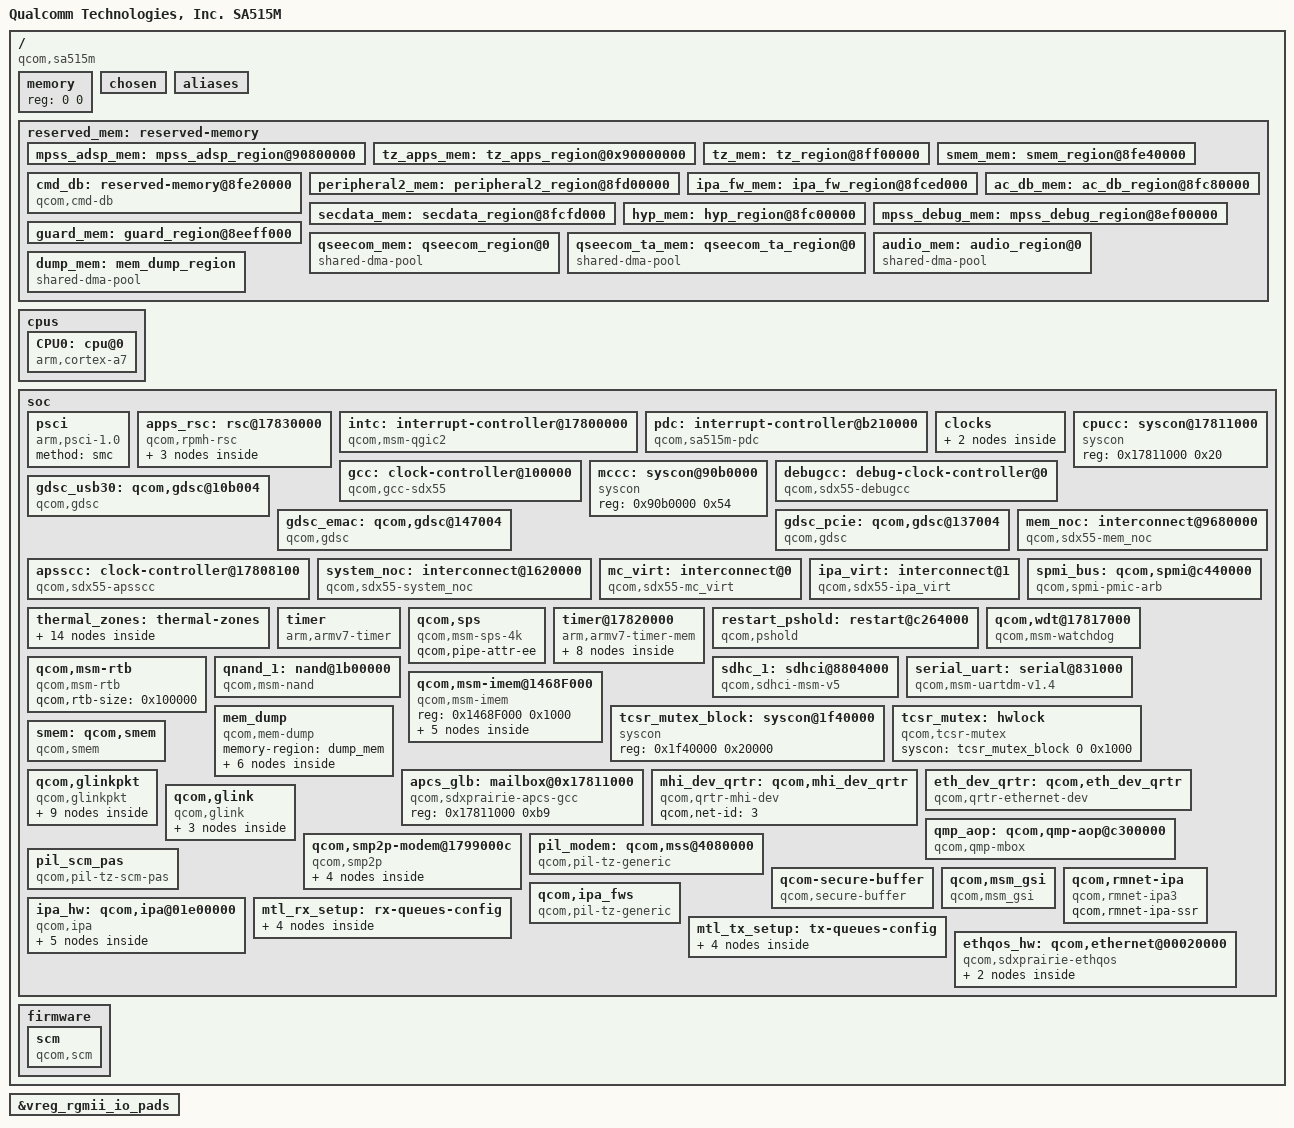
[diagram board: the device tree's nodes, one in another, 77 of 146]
#include <dt-bindings/clock/qcom,gcc-sdx55.h>
#include <dt-bindings/clock/qcom,rpmh.h>
#include <dt-bindings/interconnect/qcom,icc.h>
#include <dt-bindings/interconnect/qcom,sdx55.h>
#include <dt-bindings/interrupt-controller/arm-gic.h>
#include <dt-bindings/regulator/qcom,rpmh-regulator-levels.h>
#include <dt-bindings/soc/qcom,rpmh-rsc.h>
#include <dt-bindings/gpio/gpio.h>

/ {
	#address-cells = <1>;
	#size-cells = <1>;
	model = "Qualcomm Technologies, Inc. SA515M";
	compatible = "qcom,sa515m";
	qcom,msm-id = <418 0x10000>;

	interrupt-parent = <&intc>;

	memory { device_type = "memory"; reg = <0 0>; };

	chosen: chosen { };

	aliases {
		pci-domain0 = &pcie0; /* PCIe0 domain */
		sdhc1 = &sdhc_1; /* SDC1 eMMC/SD/SDIO slot */
	};

	reserved_mem: reserved-memory {
		#address-cells = <1>;
		#size-cells = <1>;
		ranges;

		mpss_adsp_mem: mpss_adsp_region@90800000 {
			no-map;
			reg = <0x90800000 0xe000000>;
			label = "mpss_adsp_mem";
		};

		tz_apps_mem: tz_apps_region@0x90000000 {
			no-map;
			reg = <0x90000000 0x500000>;
			label = "tz_apps_mem";
		};

		tz_mem: tz_region@8ff00000 {
			no-map;
			reg = <0x8ff00000 0x100000>;
			label = "tz_mem";
		};

		smem_mem: smem_region@8fe40000 {
			no-map;
			reg = <0x8fe40000 0xc0000>;
			label = "smem_mem";
		};

		cmd_db: reserved-memory@8fe20000 {
			compatible = "qcom,cmd-db";
			no-map;
			reg = <0x8fe20000 0x20000>;
		};

		peripheral2_mem: peripheral2_region@8fd00000 {
			no-map;
			reg = <0x8fd00000 0x120000>;
			label = "peripheral2_mem";
		};

		ipa_fw_mem: ipa_fw_region@8fced000 {
			no-map;
			reg = <0x8fced000 0x10000>;
			label = "ipa_fw_mem";
		};

		secdata_mem: secdata_region@8fcfd000 {
			no-map;
			reg = <0x8fcfd000 0x1000>;
			label = "secdata_mem";
		};

		ac_db_mem: ac_db_region@8fc80000 {
			no-map;
			reg = <0x8fc80000 0x40000>;
			label = "ac_db_mem";
		};

		hyp_mem: hyp_region@8fc00000 {
			no-map;
			reg = <0x8fc00000 0x80000>;
			label = "hyp_mem";
		};

		mpss_debug_mem: mpss_debug_region@8ef00000 {
			no-map;
			reg = <0x8ef00000 0x800000>;
			label = "mpss_debug_mem";
		};

		guard_mem: guard_region@8eeff000 {
			no-map;
			reg = <0x8eeff000 0x1000>;
			label = "guard_mem";
		};

		qseecom_mem: qseecom_region@0 {
			compatible = "shared-dma-pool";
			reusable;
			alignment = <0x400000>;
			size = <0x1400000>;
		};

		qseecom_ta_mem: qseecom_ta_region@0 {
			compatible = "shared-dma-pool";
			reusable;
			alignment = <0x400000>;
			size = <0x400000>;
		};

		audio_mem: audio_region@0 {
			compatible = "shared-dma-pool";
			no-map;
			size = <0x400000>;
		};

		dump_mem: mem_dump_region {
			compatible = "shared-dma-pool";
			reusable;
			size = <0x400000>;
		};
	};

	cpus {
		#size-cells = <0>;
		#address-cells = <1>;

		CPU0: cpu@0 {
			device_type = "cpu";
			compatible = "arm,cortex-a7";
			reg = <0x0>;
			enable-method = "psci";
			cpu-idle-states = <&A7_SPC &A7_PC &CX_MIN>;
			#cooling-cells = <2>;
		};
	};

	soc: soc { };

	firmware: firmware {};
};

&soc {
	#address-cells = <1>;
	#size-cells = <1>;
	ranges;

	psci {
		compatible = "arm,psci-1.0";
		method = "smc";
	};

	apps_rsc: rsc@17830000 {
		label = "apps_rsc";
		compatible = "qcom,rpmh-rsc";
		reg = <0x17830000 0x10000>,
		      <0x17840000 0x10000>;
		reg-names = "drv-0", "drv-1";
		interrupts = <GIC_SPI 16 IRQ_TYPE_LEVEL_HIGH>,
			     <GIC_SPI 17 IRQ_TYPE_LEVEL_HIGH>;
		qcom,tcs-offset = <0xd00>;
		qcom,drv-id = <1>;
		qcom,tcs-config = <ACTIVE_TCS  2>,
				  <SLEEP_TCS   2>,
				  <WAKE_TCS    2>,
				  <CONTROL_TCS 1>;

		rpmhcc: qcom,rpmh {
			compatible = "qcom,sdx55-rpmh-clk";
			clocks = <&xo_board>;
			clock-names = "xo";
			#clock-cells = <1>;
		};

		apps_bcm_voter: bcm_voter {
			compatible = "qcom,bcm-voter";
		};

		system_pm {
			compatible = "qcom,system-pm";
		};
	};

	intc: interrupt-controller@17800000 {
		compatible = "qcom,msm-qgic2";
		interrupt-controller;
		interrupt-parent = <&intc>;
		#interrupt-cells = <3>;
		reg = <0x17800000 0x1000>,
		      <0x17802000 0x1000>;
	};

	pdc: interrupt-controller@b210000 {
		compatible = "qcom,sa515m-pdc";
		reg = <0xb210000 0x30000>,
		      <0xb204900 0x700>;
		reg-names = "base", "mux-base";
		qcom,pdc-ranges = <0 147 52>;
		qcom,pdc-mux-ranges = <20 28 0>, <21 32 1>, <22 35 2>,
				      <23 57 3>, <24 49 4>, <25 58 5>;
		#interrupt-cells = <2>;
		interrupt-parent = <&intc>;
		interrupt-controller;
	};

	clocks {
		xo_board: xo-board {
			compatible = "fixed-clock";
			clock-frequency = <38400000>;
			clock-output-names = "xo_board";
			#clock-cells = <0>;
		};

		sleep_clk: sleep-clk {
			compatible = "fixed-clock";
			clock-frequency = <32000>;
			clock-output-names = "sleep_clk";
			#clock-cells = <0>;
		};
	};

	gcc: clock-controller@100000 {
		compatible = "qcom,gcc-sdx55", "syscon";
		reg = <0x100000 0x1f0000>;
		reg-names = "cc_base";
		clocks = <&rpmhcc RPMH_CXO_CLK>, <&rpmhcc RPMH_CXO_CLK_A>,
			<&sleep_clk>;
		clock-names = "bi_tcxo", "bi_tcxo_ao", "sleep_clk";
		vdd_cx-supply = <&VDD_CX_LEVEL>;
		vdd_cx_ao-supply = <&VDD_CX_LEVEL_AO>;
		vdd_mx-supply = <&VDD_MX_LEVEL>;
		#clock-cells = <1>;
		#reset-cells = <1>;
	};

	cpucc: syscon@17811000 {
		compatible = "syscon";
		reg = <0x17811000 0x20>;
	};

	mccc: syscon@90b0000 {
		compatible = "syscon";
		reg = <0x90b0000 0x54>;
	};

	debugcc: debug-clock-controller@0 {
		compatible = "qcom,sdx55-debugcc";
		qcom,gcc = <&gcc>;
		qcom,apsscc = <&cpucc>;
		qcom,mccc = <&mccc>;
		clock-names = "xo_clk_src";
		clocks = <&rpmhcc RPMH_CXO_CLK>;
		#clock-cells = <1>;
	};

	/* GDSCs in Global CC */
	gdsc_usb30: qcom,gdsc@10b004 {
		compatible = "qcom,gdsc";
		regulator-name = "gdsc_usb30";
		reg = <0x10b004 0x4>;
	};

	gdsc_emac: qcom,gdsc@147004 {
		compatible = "qcom,gdsc";
		regulator-name = "gdsc_emac";
		reg = <0x147004 0x4>;
	};

	gdsc_pcie: qcom,gdsc@137004 {
		compatible = "qcom,gdsc";
		regulator-name = "gdsc_pcie";
		reg = <0x137004 0x4>;
	};

	apsscc: clock-controller@17808100 {
		compatible = "qcom,sdx55-apsscc";
		clocks = <&rpmhcc RPMH_CXO_CLK_A>,
			<&gcc GPLL0>;
		clock-names = "bi_tcxo_ao", "gpll0_out_even";
		reg = <0x17810008 0x8>,
			<0x17808100 0x44>;
		reg-names = "apcs_cmd" , "apcs_pll";
		vdd-pll-supply = <&VDD_CX_LEVEL_AO>;
		cpu-vdd-supply = <&VDD_CX_LEVEL_AO>;
		qcom,speed0-bin-v0 =
			< 0 0>,
			<  345600000 RPMH_REGULATOR_LEVEL_LOW_SVS>,
			<  576000000 RPMH_REGULATOR_LEVEL_SVS>,
			< 1094400000 RPMH_REGULATOR_LEVEL_NOM>,
			< 1555200000 RPMH_REGULATOR_LEVEL_TURBO>;
		#clock-cells = <1>;
	};

	system_noc: interconnect@1620000 {
		compatible = "qcom,sdx55-system_noc";
		reg = <0x1620000 0x31200>;
		#interconnect-cells = <1>;
		qcom,bcm-voter-names = "hlos";
		qcom,bcm-voters = <&apps_bcm_voter>;
	};

	mem_noc: interconnect@9680000 {
		compatible = "qcom,sdx55-mem_noc";
		reg = <0x9680000 0x27200>;
		#interconnect-cells = <1>;
		qcom,bcm-voter-names = "hlos";
		qcom,bcm-voters = <&apps_bcm_voter>;
	};

	mc_virt: interconnect@0 {
		compatible = "qcom,sdx55-mc_virt";
		#interconnect-cells = <1>;
		qcom,bcm-voter-names = "hlos";
		qcom,bcm-voters = <&apps_bcm_voter>;
	};

	ipa_virt: interconnect@1 {
		compatible = "qcom,sdx55-ipa_virt";
		#interconnect-cells = <1>;
		qcom,bcm-voter-names = "hlos";
		qcom,bcm-voters = <&apps_bcm_voter>;
	};

	spmi_bus: qcom,spmi@c440000 {
		compatible = "qcom,spmi-pmic-arb";
		reg = <0xc440000 0xd00>,
		      <0xc600000 0xff0110>,
		      <0xe600000 0x7fa0>,
		      <0xe700000 0x40>,
		      <0xc40a000 0xb00>;
		reg-names = "core", "chnls", "obsrvr", "intr", "cnfg";
		interrupts-extended = <&pdc 1 IRQ_TYPE_LEVEL_HIGH>;
		interrupt-names = "periph_irq";
		qcom,ee = <0>;
		qcom,channel = <0>;
		#address-cells = <2>;
		#size-cells = <0>;
		interrupt-controller;
		#interrupt-cells = <4>;
		cell-index = <0>;
	};

	thermal_zones: thermal-zones {
	};

	timer {
		compatible = "arm,armv7-timer";
		interrupts = <1 13 0xf08>,
			<1 12 0xf08>,
			<1 10 0xf08>,
			<1 11 0xf08>;
		clock-frequency = <19200000>;
	};

	qcom,sps {
		compatible = "qcom,msm-sps-4k";
		qcom,pipe-attr-ee;
	};

	timer@17820000 {
		#address-cells = <1>;
		#size-cells = <1>;
		ranges;
		compatible = "arm,armv7-timer-mem";
		reg = <0x17820000 0x1000>;
		clock-frequency = <19200000>;

		frame@17821000 {
			frame-number = <0>;
			interrupts = <0 7 0x4>,
				     <0 6 0x4>;
			reg = <0x17821000 0x1000>,
			      <0x17822000 0x1000>;
		};

		frame@17823000 {
			frame-number = <1>;
			interrupts = <0 8 0x4>;
			reg = <0x17823000 0x1000>;
			status = "disabled";
		};

		frame@17824000 {
			frame-number = <2>;
			interrupts = <0 9 0x4>;
			reg = <0x17824000 0x1000>;
			status = "disabled";
		};

		frame@17825000 {
			frame-number = <3>;
			interrupts = <0 10 0x4>;
			reg = <0x17825000 0x1000>;
			status = "disabled";
		};

		frame@17826000 {
			frame-number = <4>;
			interrupts = <0 11 0x4>;
			reg = <0x17826000 0x1000>;
			status = "disabled";
		};

		frame@17827000 {
			frame-number = <5>;
			interrupts = <0 12 0x4>;
			reg = <0x17827000 0x1000>;
			status = "disabled";
		};

		frame@17828000 {
			frame-number = <6>;
			interrupts = <0 13 0x4>;
			reg = <0x17828000 0x1000>;
			status = "disabled";
		};

		frame@17829000 {
			frame-number = <7>;
			interrupts = <0 14 0x4>;
			reg = <0x17829000 0x1000>;
			status = "disabled";
		};
	};

	restart_pshold: restart@c264000 {
		compatible = "qcom,pshold";
		reg = <0xc264000 0x4>,
		      <0x1fd3000 0x4>,
		      <0x00786070 0x4>;
		reg-names = "pshold-base", "tcsr-boot-misc-detect",
				"boot-config";
		qcom,boot-config-shift = <4>;
	};

	qcom,wdt@17817000 {
		compatible = "qcom,msm-watchdog";
		reg = <0x17817000 0x1000>;
		reg-names = "wdt-base";
		interrupts = <1 3 0>, <1 2 0>;
		qcom,bark-time = <11000>;
		qcom,pet-time = <9360>;
		qcom,wakeup-enable;
	};

	qcom,msm-rtb {
		compatible = "qcom,msm-rtb";
		qcom,rtb-size = <0x100000>;
	};


	qnand_1: nand@1b00000 {
		compatible = "qcom,msm-nand";
		reg =   <0x01b00000 0x1000>,
			<0x01b04000 0x1c000>;
		reg-names =     "nand_phys",
				"bam_phys";
		qcom,reg-adjustment-offset = <0x4000>;

		interrupts = <0 135 0>;
		interrupt-names = "bam_irq";

		qcom,msm-bus,name = "qpic_nand";
		qcom,msm-bus,num-cases = <2>;
		qcom,msm-bus,num-paths = <1>;
		qcom,msm-bus,vectors-KBps =
			<91 512 0 0>,
		/* Voting for max b/w on PNOC bus for now */
			<91 512 400000 400000>;

		clock-names = "core_clk";
		clocks = <&rpmhcc RPMH_QPIC_CLK>;

		status = "ok";
	};


	sdhc_1: sdhci@8804000 {
		compatible = "qcom,sdhci-msm-v5";
		reg = <0x8804000 0x1000>;
		reg-names = "hc_mem";

		interrupts = <GIC_SPI 210 IRQ_TYPE_NONE>,
			<GIC_SPI 227 IRQ_TYPE_NONE>;
		interrupt-names = "hc_irq", "pwr_irq";

		bus-width = <4>;

		qcom,msm-bus,name = "sdhc1";
		qcom,msm-bus,num-cases = <8>;
		qcom,msm-bus,num-paths = <1>;
		qcom,msm-bus,vectors-KBps =  <78 512 0 0>, /* No vote */
				<78 512 1600 3200>,    /* 400 KB/s*/
				<78 512 80000 160000>, /* 20 MB/s */
				<78 512 100000 200000>, /* 25 MB/s */
				<78 512 200000 400000>, /* 50 MB/s */
				<78 512 400000 800000>, /* 100 MB/s */
				<78 512 400000 800000>, /* 200 MB/s */
				<78 512 2048000 4096000>; /* Max. bandwidth */
		qcom,bus-bw-vectors-bps = <0 400000 20000000 25000000 50000000
						100000000 200000000 4294967295>;

		clocks = <&gcc GCC_SDCC1_AHB_CLK>,
			<&gcc GCC_SDCC1_APPS_CLK>;
		clock-names = "iface", "core";

		//qcom,restore-after-cx-collapse;

		/* DLL HSR settings. Refer go/hsr - <Target> DLL settings */
		qcom,dll-hsr-list = <0x0007642c 0xa800 0x10
					0x2c010800 0x80040868>;

		qcom,devfreq,freq-table = <50000000 200000000>;
		no-sdio;
		no-mmc;

		status = "disabled";
	};


	serial_uart: serial@831000 {
		compatible = "qcom,msm-uartdm-v1.4", "qcom,msm-uartdm";
		reg = <0x831000 0x200>;
		interrupts = <0 26 0>;
		clocks = <&gcc GCC_BLSP1_UART3_APPS_CLK>,
			<&gcc GCC_BLSP1_AHB_CLK>;
		clock-names = "core", "iface";
		pinctrl-names = "default", "sleep";
		pinctrl-0 = <&uart3_console_active>;
		pinctrl-1 = <&uart3_console_sleep>;
		status = "ok";
	};

	qcom,msm-imem@1468F000 {
		compatible = "qcom,msm-imem";
		reg = <0x1468F000 0x1000>; /* Address and size of IMEM */
		ranges = <0x0 0x1468F000 0x1000>;
		#address-cells = <1>;
		#size-cells = <1>;

		mem_dump_table@10 {
			compatible = "qcom,msm-imem-mem_dump_table";
			reg = <0x10 0x8>;
		};

		restart_reason@65c {
			compatible = "qcom,msm-imem-restart_reason";
			reg = <0x65c 0x4>;
		};

		boot_stats@6b0 {
			compatible = "qcom,msm-imem-boot_stats";
			reg = <0x6b0 0x20>;
		};

		pil@94c {
			compatible = "qcom,msm-imem-pil";
			reg = <0x94c 0xc8>;
		};

		diag_dload@c8 {
			compatible = "qcom,msm-imem-diag-dload";
			reg = <0xc8 0xc8>;
		};
	};

	mem_dump {
		compatible = "qcom,mem-dump";
		memory-region = <&dump_mem>;

		rpmh {
			qcom,dump-size = <0x200000>;
			qcom,dump-id = <0xec>;
		};

		rpm_sw {
			qcom,dump-size = <0x28000>;
			qcom,dump-id = <0xea>;
		};

		pmic {
			qcom,dump-size = <0x80000>;
			qcom,dump-id = <0xe4>;
		};


		tmc_etf {
			qcom,dump-size = <0x4000>;
			qcom,dump-id = <0xf1>;
		};

		etr_reg {
			qcom,dump-size = <0x1000>;
			qcom,dump-id = <0x100>;
		};

		etf_reg {
			qcom,dump-size = <0x1000>;
			qcom,dump-id = <0x102>;

		};
	};

	tcsr_mutex_block: syscon@1f40000 {
		compatible = "syscon";
		reg = <0x1f40000 0x20000>;
	};

	tcsr_mutex: hwlock {
		compatible = "qcom,tcsr-mutex";
		syscon = <&tcsr_mutex_block 0 0x1000>;
		#hwlock-cells = <1>;
	};

	smem: qcom,smem {
		compatible = "qcom,smem";
		memory-region = <&smem_mem>;
		hwlocks = <&tcsr_mutex 3>;
	};

	apcs_glb: mailbox@0x17811000 {
		compatible = "qcom,sdxprairie-apcs-gcc";
		reg = <0x17811000 0xb9>;
		#mbox-cells = <1>;
	};

	mhi_dev_qrtr: qcom,mhi_dev_qrtr {
		compatible = "qcom,qrtr-mhi-dev";
		qcom,net-id = <3>;
	};

	eth_dev_qrtr: qcom,eth_dev_qrtr {
		compatible = "qcom,qrtr-ethernet-dev";
		qcom,net-id = <4>;
		qcom,low-latency;
	};

	qcom,glinkpkt {
		compatible = "qcom,glinkpkt";

		qcom,glinkpkt-at-mdm0 {
			qcom,glinkpkt-edge = "mpss";
			qcom,glinkpkt-ch-name = "DS";
			qcom,glinkpkt-dev-name = "at_mdm0";
		};

		qcom,glinkpkt-data5-cntl {
			qcom,glinkpkt-edge = "mpss";
			qcom,glinkpkt-ch-name = "DATA5_CNTL";
			qcom,glinkpkt-dev-name = "smdcntl0";
		};

		qcom,glinkpkt-data6-cntl {
			qcom,glinkpkt-edge = "mpss";
			qcom,glinkpkt-ch-name = "DATA6_CNTL";
			qcom,glinkpkt-dev-name = "smdcntl1";
		};

		qcom,glinkpkt-data40-cntl {
			qcom,glinkpkt-edge = "mpss";
			qcom,glinkpkt-ch-name = "DATA40_CNTL";
			qcom,glinkpkt-dev-name = "smdcntl8";
		};

		qcom,glinkpkt-data1 {
			qcom,glinkpkt-edge = "mpss";
			qcom,glinkpkt-ch-name = "DATA1";
			qcom,glinkpkt-dev-name = "smd7";
		};

		qcom,glinkpkt-data4 {
			qcom,glinkpkt-edge = "mpss";
			qcom,glinkpkt-ch-name = "DATA4";
			qcom,glinkpkt-dev-name = "smd8";
		};

		qcom,glinkpkt-data11 {
			qcom,glinkpkt-edge = "mpss";
			qcom,glinkpkt-ch-name = "DATA11";
			qcom,glinkpkt-dev-name = "smd11";
		};

		qcom,glinkpkt-data21 {
			qcom,glinkpkt-edge = "mpss";
			qcom,glinkpkt-ch-name = "DATA21";
			qcom,glinkpkt-dev-name = "smd21";
		};

		qcom,glinkpkt-data22 {
			qcom,glinkpkt-edge = "mpss";
			qcom,glinkpkt-ch-name = "DATA22";
			qcom,glinkpkt-dev-name = "smd22";
		};
	};

	qmp_aop: qcom,qmp-aop@c300000 {
		compatible = "qcom,qmp-mbox";
		reg = <0xc310000 0x1000>, <0x17811008 0x4>;
		reg-names = "msgram", "irq-reg-base";
		qcom,irq-mask = <0x1>;
		interrupts = <GIC_SPI 221 IRQ_TYPE_EDGE_RISING>;

		label = "aop";
		qcom,early-boot;
		priority = <0>;
		mbox-desc-offset = <0x0>;
		#mbox-cells = <1>;
	};

	qcom,glink {
		compatible = "qcom,glink";
		#address-cells = <1>;
		#size-cells = <1>;
		ranges;

		glink_modem: modem {
			qcom,remote-pid = <1>;
			transport = "smem";
			mboxes = <&apcs_glb 15>;
			mbox-names = "mpss_smem";
			interrupts = <GIC_SPI 114 IRQ_TYPE_EDGE_RISING>;

			label = "modem";
			qcom,glink-label = "mpss";

			qcom,modem_qrtr {
				qcom,glink-channels = "IPCRTR";
				qcom,intents = <0x800  5
						0x2000 3
						0x4400 2>;
			};

			qcom,apr_tal_rpmsg {
				qcom,glink-channels = "apr_audio_svc";
				qcom,intents = <0x200 20>;
			};
		};
	};

	qcom,smp2p-modem@1799000c {
		compatible = "qcom,smp2p";
		qcom,smem = <435>, <428>;
		interrupts = <GIC_SPI 113 IRQ_TYPE_EDGE_RISING>;
		mboxes = <&apcs_glb 14>;
		qcom,local-pid = <0>;
		qcom,remote-pid = <1>;

		modem_smp2p_out: master-kernel {
			qcom,entry-name = "master-kernel";
			#qcom,smem-state-cells = <1>;
		};

		modem_smp2p_in: slave-kernel {
			qcom,entry-name = "slave-kernel";
			interrupt-controller;
			#interrupt-cells = <2>;
		};

		smp2p_ipa_1_out: qcom,smp2p-ipa-1-out {
			qcom,entry-name = "ipa";
			#qcom,smem-state-cells = <1>;
		};

		/* ipa - inbound entry from mss */
		smp2p_ipa_1_in: qcom,smp2p-ipa-1-in {
			qcom,entry-name = "ipa";
			interrupt-controller;
			#interrupt-cells = <2>;
		};
	};

	pil_modem: qcom,mss@4080000 {
		compatible = "qcom,pil-tz-generic";
		reg = <0x4080000 0x100>;

		clocks = <&rpmhcc RPMH_CXO_CLK>;
		clock-names = "xo";
		qcom,proxy-clock-names = "xo";

		vdd_cx-supply = <&VDD_CX_LEVEL>;
		qcom,vdd_cx-uV-uA = <RPMH_REGULATOR_LEVEL_TURBO 100000>;
		vdd_mss-supply = <&VDD_MODEM_LEVEL>;
		qcom,vdd_mss-uV-uA = <RPMH_REGULATOR_LEVEL_TURBO 100000>;
		qcom,proxy-reg-names = "vdd_cx", "vdd_mss";

		qcom,firmware-name = "modem";
		memory-region = <&mpss_adsp_mem>;
		qcom,pas-id = <4>;
		qcom,smem-id = <421>;
		qcom,sysmon-id = <0>;
		qcom,ssctl-instance-id = <0x22>;
		qcom,minidump-id = <3>;

		interrupts-extended = <&intc 0 250 1>,
				<&modem_smp2p_in 0 0>,
				<&modem_smp2p_in 2 0>,
				<&modem_smp2p_in 1 0>,
				<&modem_smp2p_in 3 0>,
				<&modem_smp2p_in 7 0>;

		interrupt-names = "qcom,wdog",
				"qcom,err-fatal",
				"qcom,proxy-unvote",
				"qcom,err-ready",
				"qcom,stop-ack",
				"qcom,shutdown-ack";

		qcom,smem-states = <&modem_smp2p_out 0>;
		qcom,smem-state-names = "qcom,force-stop";

		status = "ok";
	};

	pil_scm_pas {
		compatible = "qcom,pil-tz-scm-pas";
		interconnects = <&system_noc MASTER_CRYPTO
				&mc_virt SLAVE_EBI1>;
	};

	qcom-secure-buffer {
		compatible = "qcom,secure-buffer";
	};

	qcom,msm_gsi {
		compatible = "qcom,msm_gsi";
	};

	qcom,rmnet-ipa {
		compatible = "qcom,rmnet-ipa3";
		qcom,rmnet-ipa-ssr;
	};

	qcom,ipa_fws {
		compatible = "qcom,pil-tz-generic";
		qcom,pas-id = <0xf>;
		qcom,firmware-name = "ipa_fws";
		qcom,pil-force-shutdown;
	};

	ipa_hw: qcom,ipa@01e00000 {
		compatible = "qcom,ipa";
		mboxes = <&qmp_aop 0>;
		reg = <0x1e00000 0x84000>,
		      <0x1e04000 0x23000>;
		reg-names = "ipa-base", "gsi-base";
		interrupts =
			<0 241 IRQ_TYPE_NONE>,
			<0 47 IRQ_TYPE_NONE>;
		interrupt-names = "ipa-irq", "gsi-irq";
		qcom,ipa-hw-ver = <17>; /* IPA core version = IPAv4.5 */
		qcom,ipa-hw-mode = <0>;
		qcom,ee = <0>;
		qcom,use-ipa-tethering-bridge;
		qcom,mhi-event-ring-id-limits = <9 14>; /* start and end */
		qcom,modem-cfg-emb-pipe-flt;
		qcom,use-ipa-pm;
		qcom,use-xbl-boot;
		qcom,arm-smmu;
		qcom,wlan-ce-db-over-pcie;
		qcom,bandwidth-vote-for-ipa;
		qcom,msm-bus,name = "ipa";
		qcom,ipa-wdi2_over_gsi;
		qcom,ipa-endp-delay-wa;
		qcom,ipa-config-is-auto;
		qcom,ipa-wdi3-holb-2g = <8>;
		qcom,ipa-wdi3-holb-5g = <15>;
		qcom,msm-bus,num-cases = <5>;
		qcom,msm-bus,num-paths = <5>;
		qcom,wan-aggr-time-limit = <200>;
		qcom,lan-aggr-time-limit = <200>;
		qcom,rndis-aggr-time-limit = <200>;
		qcom,max_num_smmu_cb = <3>;
		qcom,interconnect,num-cases = <5>;
		qcom,interconnect,num-paths = <5>;
		interconnects = <&system_noc MASTER_IPA &system_noc SLAVE_SNOC_MEM_NOC_GC>,
				<&mem_noc MASTER_SNOC_GC_MEM_NOC &mc_virt SLAVE_EBI1>,
				<&system_noc MASTER_IPA &system_noc SLAVE_IMEM>,
				<&mem_noc MASTER_APPSS_PROC &system_noc SLAVE_IPA_CFG>,
				<&ipa_virt MASTER_IPA_CORE &ipa_virt SLAVE_IPA_CORE>;
		interconnect-names = "ipa_to_memnoc", "ipa_to_ebi1", "ipa_to_imem", "appsproc_to_ipacfg", "ipacore_to_ipacore";

		/* No vote */
		qcom,no-vote =
		<0 0 0 0 0 0 0 0 0 0>;

		/* SVS2 */
		qcom,svs2 =
		<150000 600000 150000 1804000 75000 450000 0 171400 0 150>;

		/* SVS */
		qcom,svs =
		<625000 1000000 625000 3072000 312500 750000 0 200000 0 250>;

		/* NOMINAL */
		qcom,nominal =
		<1250000 2000000 1250000 6220800 625000 1500000 0 400000 0 500>;

		/* TURBO */
		qcom,turbo =
		<2000000 2400000 2000000 7219200 1000000 1920000 0 533320 0 600>;

		qcom,throughput-threshold = <310 600 1000>;
		qcom,scaling-exceptions = <>;

		/* ipa tz unlock registers */
		qcom,ipa-tz-unlock-reg =
			<0x4043583c 0x1000>; /* 32-bit reg addr and size*/

		ipa_smmu_ap: ipa_smmu_ap {
			compatible = "qcom,ipa-smmu-ap-cb";
			iommus = <&apps_smmu 0x5E0 0x0>;
			qcom,iommu-dma-addr-pool = <0x20000000 0x40000000>;
			qcom,additional-mapping =
				/* modem tables in IMEM */
				<0x14688000 0x14688000 0x3000>;
			qcom,ipa-q6-smem-size = <36864>;
			qcom,iommu-dma = "fastmap";
			qcom,geometry-mapping = <0x0 0xF0000000>;
		};

		ipa_smmu_wlan: ipa_smmu_wlan {
			compatible = "qcom,ipa-smmu-wlan-cb";
			iommus = <&apps_smmu 0x5E1 0x0>;
			qcom,iommu-dma-addr-pool = <0x60000000 0x10000000>;
		};

		ipa_smmu_uc: ipa_smmu_uc {
			compatible = "qcom,ipa-smmu-uc-cb";
			iommus = <&apps_smmu 0x5E2 0x0>;
			qcom,iommu-dma-addr-pool = <0x40000000 0x20000000>;
		};

		/* smp2p information */
		qcom,smp2p_map_ipa_1_out {
			compatible = "qcom,smp2p-map-ipa-1-out";
			qcom,smem-states = <&smp2p_ipa_1_out 0>;
			qcom,smem-state-names = "ipa-smp2p-out";
		};

		qcom,smp2p_map_ipa_1_in {
			compatible = "qcom,smp2p-map-ipa-1-in";
			interrupts-extended = <&smp2p_ipa_1_in 0 0>;
			interrupt-names = "ipa-smp2p-in";
		};
	};

	mtl_rx_setup: rx-queues-config {
		snps,rx-queues-to-use = <4>;
		snps,rx-sched-sp;

		queue0 {
			snps,dcb-algorithm;
			snps,map-to-dma-channel = <0x0>;
			snps,route-up;
			snps,route-ptp;
			snps,route-dcbcp;
		};

		queue1 {
			snps,dcb-algorithm;
			snps,map-to-dma-channel = <0x1>;
			snps,route-avcp;
			snps,route-multi-broad;
		};

		queue2 {
			snps,avb-algorithm;
			snps,map-to-dma-channel = <0x2>;
		};

		queue3 {
			snps,avb-algorithm;
			snps,map-to-dma-channel = <0x3>;
			snps,priority = <0x0C>;
		};
	};

	mtl_tx_setup: tx-queues-config {
		snps,tx-queues-to-use = <5>;
		snps,tx-sched-sp;
		queue0 {
			snps,dcb-algorithm;
		};

		queue1 {
			snps,dcb-algorithm;
		};

		queue2 {
			snps,avb-algorithm;
			snps,send_slope = <0x1000>;
			snps,idle_slope = <0x1000>;
			snps,high_credit = <0x3E800>;
			snps,low_credit = <0xFFC18000>;
		};

		queue3 {
			snps,avb-algorithm;
			snps,send_slope = <0x1000>;
			snps,idle_slope = <0x1000>;
			snps,high_credit = <0x3E800>;
			snps,low_credit = <0xFFC18000>;
		};
	};

	ethqos_hw: qcom,ethernet@00020000 {
		compatible = "qcom,sdxprairie-ethqos";
		qcom,arm-smmu;
		reg = <0x20000 0x10000>,
			<0x36000 0x100>,
			<0xf100000 0x300000>;
		reg-names = "stmmaceth", "rgmii","tlmm-central-base";
		clocks = <&gcc GCC_ETH_AXI_CLK>,
			<&gcc GCC_ETH_SLAVE_AHB_CLK>,
			<&gcc GCC_ETH_PTP_CLK>,
			<&gcc GCC_ETH_RGMII_CLK>;
		clock-names = "stmmaceth", "pclk", "ptp_ref", "rgmii";
		interrupts-extended = <&intc 0 62 4>, <&intc 0 60 4>,
			<&tlmm 90 2>, <&intc 0 290 1>, <&intc 0 291 1>;
		interrupt-names = "macirq", "eth_lpi",
			"phy-intr",	"ptp_pps_irq_0", "ptp_pps_irq_1";

		snps,tso;
		rx-fifo-depth = <16384>;
		tx-fifo-depth = <16384>;
		snps,mtl-rx-config = <&mtl_rx_setup>;
		snps,mtl-tx-config = <&mtl_tx_setup>;

		vreg_rgmii-supply = <&pmx55_vref_rgmii>;
		vreg_emac_phy-supply =  <&vreg_emac_phy>;
		vreg_rgmii_io_pads-supply = <&vreg_rgmii_io_pads>;
		gdsc_emac-supply = <&gdsc_emac>;

		qcom,phy-intr-redirect = <&tlmm 90 GPIO_ACTIVE_LOW>;
		pinctrl-names = "dev-emac_pin_pps_0", "dev-emac_pin_pps_1";
		pinctrl-0 = <&emac_pin_pps_0>;
		pinctrl-1 = <&emac_pin_pps_1>;
		snps,reset-gpios = <&tlmm 91 GPIO_ACTIVE_HIGH>;

		snps,reset-delays-us = <0 10000 100000>;
		phy-mode = "rgmii";

		ethqos_emb_smmu: ethqos_emb_smmu {
				compatible = "qcom,emac-smmu-embedded";
				iommus = <&apps_smmu 0x1c0 0xf>;
				qcom,iommu-dma = "fastmap";
				qcom,iommu-dma-addr-pool = <0x80000000 0x40000000>;
		};


		rgmii-io-macro-info {
			prg-rclk-dly = <1507>;
			config-cdr-en = <0>;
			mclk-gating-en = <1>;
			cdr-fine-phase = <1>;
			loopback-en = <0>;
			rx-prog-swap = <1>;
			tx-clk-phase-shift-en = <1>;
			dll-clock-dis = <1>;
			ddr-traffic-init-sel = <0>;
			ddr-traffic-init-sw = <0>;
			};
		};
};

#include "sa515m-pinctrl.dtsi"
#include "sa515m-blsp.dtsi"
#include "sdx55-regulator.dtsi"
#include "sa515m-ion.dtsi"
#include "msm-arm-smmu-sa515m.dtsi"
#include "sa515m-usb.dtsi"
#include "sa515m-pcie.dtsi"
#include "sa515m-pm.dtsi"
#include "sa515m-audio.dtsi"

&vreg_rgmii_io_pads {
	regulator-min-microvolt = <1800000>;
	regulator-max-microvolt = <1800000>;
};

&firmware {
	scm {
		compatible = "qcom,scm";
	};
};

&gdsc_usb30 {
	status = "ok";
};

&sdhc_1 {
	vdd-supply = <&vreg_sd_vdd>;
	qcom,vdd-voltage-level = <2950000 2950000>;
	qcom,vdd-current-level = <0 800000>;

	vdd-io-supply = <&vreg_vddpx_2>;
	qcom,vdd-io-voltage-level = <1800000 2850000>;
	qcom,vdd-io-current-level = <0 10000>;

	pinctrl-names = "default", "sleep";
	pinctrl-0 = <&sdc1_on>;
	pinctrl-1 = <&sdc1_off>;

	qcom,clk-rates = <400000 20000000 25000000 50000000 100000000
				200000000>;
	qcom,devfreq,freq-table = <50000000 200000000>;

	cd-gpios = <&tlmm 99 GPIO_ACTIVE_LOW>;
	status = "ok";
};

#include "sdxprairie-thermal.dtsi"

&thermal_zones {
	/delete-node/ pm8150b-wp-therm;
	/delete-node/ pm8150b_tz;
	/delete-node/ pm8150b-ibat-lvl0;
	/delete-node/ pm8150b-ibat-lvl1;
	/delete-node/ pm8150b-vbat-lvl0;
	/delete-node/ pm8150b-vbat-lvl1;
	/delete-node/ pm8150b-vbat-lvl2;
	/delete-node/ pm8150b-bcl-lvl0;
	/delete-node/ pm8150b-bcl-lvl1;
	/delete-node/ pm8150b-bcl-lvl2;
	/delete-node/ soc;

	/* update Tj thresholds */
	mdm-core-0-step {
		trips {
			active-config0 {
				temperature = <101000>;
				hysteresis = <5000>;
			};

			active-config1 {
				temperature = <103000>;
				hysteresis = <3000>;
			};

			active-config2 {
				temperature = <105000>;
				hysteresis = <3000>;
			};
		};
	};

	mdm-core-0-v2x-step {
		polling-delay-passive = <0>;
		polling-delay = <0>;
		thermal-sensors = <&tsens0 6>;
		thermal-governor = "step_wise";

		trips {
			tj_v2x_config0: active-config0 {
				temperature = <105000>;
				hysteresis = <5000>;
				type = "passive";
			};

			tj_v2x_config1: active-config1 {
				temperature = <110000>;
				hysteresis = <5000>;
				type = "passive";
			};

			tj_v2x_config2: active-config2 {
				temperature = <115000>;
				hysteresis = <5000>;
				type = "passive";
			};
		};

		cooling-maps {
			modem_tj0_v2x_cdev {
				trip = <&tj_v2x_config0>;
				cooling-device = <&modem_v2x 1 1>;
			};

			modem_tj1_v2x_cdev {
				trip = <&tj_v2x_config1>;
				cooling-device = <&modem_v2x 2 2>;
			};

			modem_tj2_v2x_cdev {
				trip = <&tj_v2x_config2>;
				cooling-device = <&modem_v2x 3 3>;
			};
		};
	};
};
